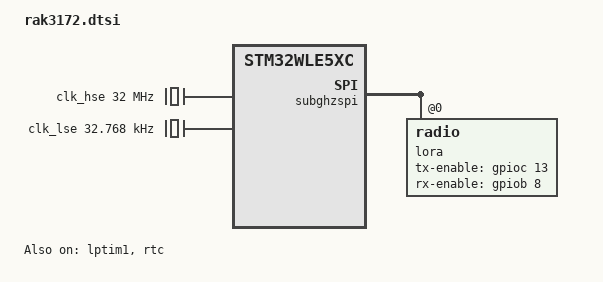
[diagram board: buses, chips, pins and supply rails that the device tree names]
/*
 * Copyright (c) 2024 Teslabs Engineering S.L.
 * Copyright (c) 2024 Kenneth Lu <kuohsianglu@gmail.com>
 * SPDX-License-Identifier: Apache-2.0
 */

#include <st/wl/stm32wle5Xc.dtsi>
#include <st/wl/stm32wle5ccux-pinctrl.dtsi>

&clk_hse {
	status = "okay";
	clock-frequency = <DT_FREQ_M(32)>;
};

&clk_lse {
	status = "okay";
	clock-frequency = <32768>;
};

&pll {
	div-m = <1>;
	mul-n = <6>;
	div-r = <4>;
	div-q = <4>;
	clocks = <&clk_hse>;
	status = "okay";
};

&rcc {
	clocks = <&pll>;
	clock-frequency = <DT_FREQ_M(48)>;
	cpu1-prescaler = <1>;
	ahb3-prescaler = <1>;
	apb1-prescaler = <1>;
	apb2-prescaler = <1>;
};

&lptim1 {
	clocks = <&rcc STM32_CLOCK(APB1, 31)>,
		 <&rcc STM32_SRC_LSE LPTIM1_SEL(3)>;
	status = "okay";
};

&rtc {
	clocks = <&rcc STM32_CLOCK(APB1, 10)>,
		 <&rcc STM32_SRC_LSE RTC_SEL(1)>;
	status = "okay";
};

&subghzspi {
	status = "okay";

	lora: radio@0 {
		status = "okay";
		tx-enable-gpios = <&gpioc 13 GPIO_ACTIVE_HIGH>; /* FE_CTRL1 */
		rx-enable-gpios = <&gpiob 8 GPIO_ACTIVE_HIGH>;  /* FE_CTRL2 */
		power-amplifier-output = "rfo-hp";
		rfo-hp-max-power = <22>;
	};
};
